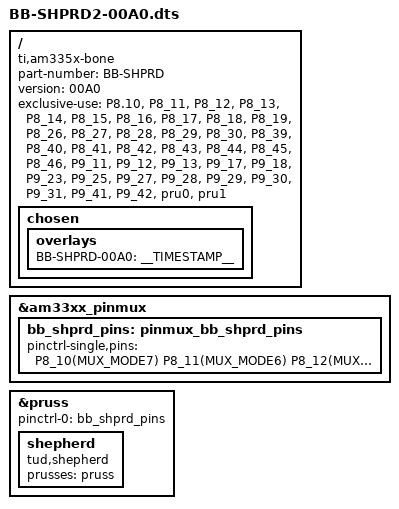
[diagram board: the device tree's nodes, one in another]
/dts-v1/;
/plugin/;
#include "am335x_pinctrl.h"

/*
// future-reference, gpio.h contains: BONE_P8_03, etc
#include <dt-bindings/gpio/gpio.h>
// future-reference, omap.h contains: MUX_MODE#, PULL_UP, INPUT_EN, AM33XX_IOPAD, AM33XX_PADCONF, etc
#include <dt-bindings/pinctrl/omap.h>
*/


/ {
   // note: (older) "ti,beaglebone" types seem to be working as well for v4.19.x-ti, but this is more future-proof
   compatible = "ti,am335x-bone", "ti,am335x-bone-black", "ti,am335x-bone-green";

   part-number = "BB-SHPRD";
   version = "00A0";

   /* This overlay uses the following resources */
   exclusive-use =

        "P8.10", /*     WD ACK */
        "P8_11", /*     pru0_dbg_Led1 */
        "P8_12", /*     pru0_dbg_Led0 */
        "P8_13", /*     EN_Shepherd */
        "P8_14", /*     target_GPIO0 */
        "P8_15", /* 	target_GPIO3 */
        "P8_16", /* 	target_GPIO2 */
        "P8_17", /* 	target_GPIO1 */
        "P8_18", /* 	BTN Sense */
        "P8_19", /* 	BTN Led */

        "P8_26", /* 	target_GPIO4 */
        "P8_27", /* 	pru1_target_batOK */
        "P8_28", /* 	pru1_dbg_Led0 */
        "P8_29", /* 	pru1_target_GPIO4 */
        "P8_30", /* 	pru1_dbg_Led1 */

        "P8_39", /* 	pru1_target_swd_clk */
        "P8_40", /* 	pru1_target_swd_io */
        "P8_41", /* 	pru1_target_uatx */
        "P8_42", /* 	pru1_target_uarx */
        "P8_43", /* 	pru1_target_GPIO2 */
        "P8_44", /* 	pru1_target_GPIO3 */
        "P8_45", /* 	pru1_target_GPIO0 */
        "P8_46", /* 	pru1_target_GPIO1 */

        "P9_11", /* 	target_io_SEL */
        "P9_12", /* 	target_io_EN */
        "P9_13", /* 	target_Pwr_SEL */

        "P9_17", /* 	target_swd_clk */
        "P9_18", /* 	target_swd_io */

        "P9_23", /* 	Mem_WP */

        "P9_25", /* 	pru/SPI_CS_ADC2_REC */

        "P9_27", /* 	pru/SPI_CS_DAC_REC */
        "P9_28", /* 	pru/SPI_CS_DAC_EMU */
        "P9_29", /* 	pru/SPI_MOSI */
        "P9_30", /* 	pru/SPI_MISO */
        "P9_31", /* 	pru/SPI_SCK */

        "P9_41", /* 	pru/SPI_CS_ADC1_REC */
        "P9_42", /* 	pru/SPI_CS_ADC_EMU */

        /* Realtime Units */
        "pru0",
        "pru1";

        // GPS
        //"P8.07", /*  GPS PPS */
        //"P8.08", /*  GPS nReset */
        //"P8.09", /*  GPS Safeboot */
        //"P9_21", /* 	GPS UART2TX */  // UART2
        //"P9_22", /* 	GPS UART2RX */

        // EEPROM
        //"P9_19", /* 	Mem_SCL */      // I2C1
        //"P9_20", /* 	Mem_SDA */

        // Target
        //"P9_24", /* 	target_uart_tx */ // UART1
        //"P9_26", /* 	target_uart_rx */

   /* Check Table 9-60 in am335x TRM */

   /* Helper to show loaded overlays under: /proc/device-tree/chosen/overlays/  */
   /* Note:
        - root-path and "chosen" seem to produce a warning with dtc, internet is not helpful
        - this is the reference solution choosen by: https://github.com/RobertCNelson/bb.org-overlays
   */
   fragment@0 {
      target-path="/";
      __overlay__ {
         chosen {
            overlays {
               BB-SHPRD-00A0 = __TIMESTAMP__;
            };
         };
      };
   };


   fragment@1 {
      target = <&am33xx_pinmux>;
      __overlay__ {
         bb_shprd_pins: pinmux_bb_shprd_pins {
            pinctrl-single,pins = <

            P8_10(MUX_MODE7)                // gpio2[4]
            P8_11(MUX_MODE6)                // pr1_pru0_pru_r30_15
            P8_12(MUX_MODE6)                // pr1_pru0_pru_r30_14
            P8_13(MUX_MODE7)                // gpio0[23]
            P8_14(MUX_MODE7 | RX_ACTIVE)    // gpio0[26]
            P8_15(MUX_MODE7 | RX_ACTIVE)    // gpio1[15]
            P8_16(MUX_MODE7 | RX_ACTIVE)    // gpio1[14]
            P8_17(MUX_MODE7 | RX_ACTIVE)    // gpio0[27]
            P8_18(MUX_MODE7 | RX_ACTIVE)    // gpio2[1]
            P8_19(MUX_MODE7)                // gpio0[22]

            P8_26(MUX_MODE7)                // gpio1[29]
            P8_27(MUX_MODE6 | RX_ACTIVE)    // pr1_pru1_pru_r31_8
            P8_28(MUX_MODE5)                // pr1_pru1_pru_r30_10
            P8_29(MUX_MODE6 | RX_ACTIVE)    // pr1_pru1_pru_r31_9
            P8_30(MUX_MODE5)                // pr1_pru1_pru_r30_11

            P8_39(MUX_MODE6 | RX_ACTIVE)    // pr1_pru1_pru_r31_6
            P8_40(MUX_MODE6 | RX_ACTIVE)    // pr1_pru1_pru_r31_7
            P8_41(MUX_MODE6 | RX_ACTIVE)    // pr1_pru1_pru_r31_4
            P8_42(MUX_MODE6 | RX_ACTIVE)    // pr1_pru1_pru_r31_5
            P8_43(MUX_MODE6 | RX_ACTIVE)    // pr1_pru1_pru_r31_2
            P8_44(MUX_MODE6 | RX_ACTIVE)    // pr1_pru1_pru_r31_3
            P8_45(MUX_MODE6 | RX_ACTIVE)    // pr1_pru1_pru_r31_0
            P8_46(MUX_MODE6 | RX_ACTIVE)    // pr1_pru1_pru_r31_1

            P9_11(MUX_MODE7)                // gpio0[30]
            P9_12(MUX_MODE7)                // gpio1[28]
            P9_13(MUX_MODE7)                // gpio0[31]

            P9_17(MUX_MODE7)                // gpio0[5]
            P9_18(MUX_MODE7 | RX_ACTIVE)    // gpio0[4]

            P9_23(MUX_MODE7)                // gpio1[17]

            P9_25(MUX_MODE5)

            P9_27(MUX_MODE5)                // pr1_pru0_pru_r30_5
            P9_28(MUX_MODE5)                // pr1_pru0_pru_r30_3
            P9_29(MUX_MODE5)                // pr1_pru0_pru_r30_1
            P9_30(MUX_MODE6 | RX_ACTIVE)    // pr1_pru0_pru_r31_2
            P9_31(MUX_MODE5)                // pr1_pru0_pru_r30_0

            P9_41B(MUX_MODE5)               // pr1_pru0_pru_r30_6
            P9_42B(MUX_MODE5)               // pr1_pru0_pru_r30_4
            >;
         };
      };
   };

   fragment@2 {
       target = <&pruss>;
       __overlay__ {
           status = "okay";
            pinctrl-names = "default";
            pinctrl-0 = <&bb_shprd_pins>;
            shepherd{
               compatible = "tud,shepherd";
               prusses = <&pruss>;
            };	
       };
   };

};
